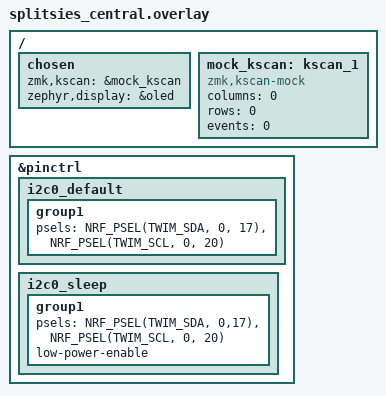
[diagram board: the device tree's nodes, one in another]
#include "splitsies.dtsi"

/{
    chosen {
        zmk,kscan = &mock_kscan;
        zephyr,display = &oled;
    };
    mock_kscan: kscan_1 {
        compatible = "zmk,kscan-mock";
        columns = <0>;
        rows = <0>;
        events = <0>;
    };
};

&pinctrl {
    i2c0_default: i2c0_default {
        group1 {
            psels = <NRF_PSEL(TWIM_SDA, 0, 17)>,
                <NRF_PSEL(TWIM_SCL, 0, 20)>;
        };
    };

    i2c0_sleep: i2c0_sleep {
        group1 {
            psels = <NRF_PSEL(TWIM_SDA, 0,17)>,
                <NRF_PSEL(TWIM_SCL, 0, 20)>;
            low-power-enable;
        };
    };	
}; 
